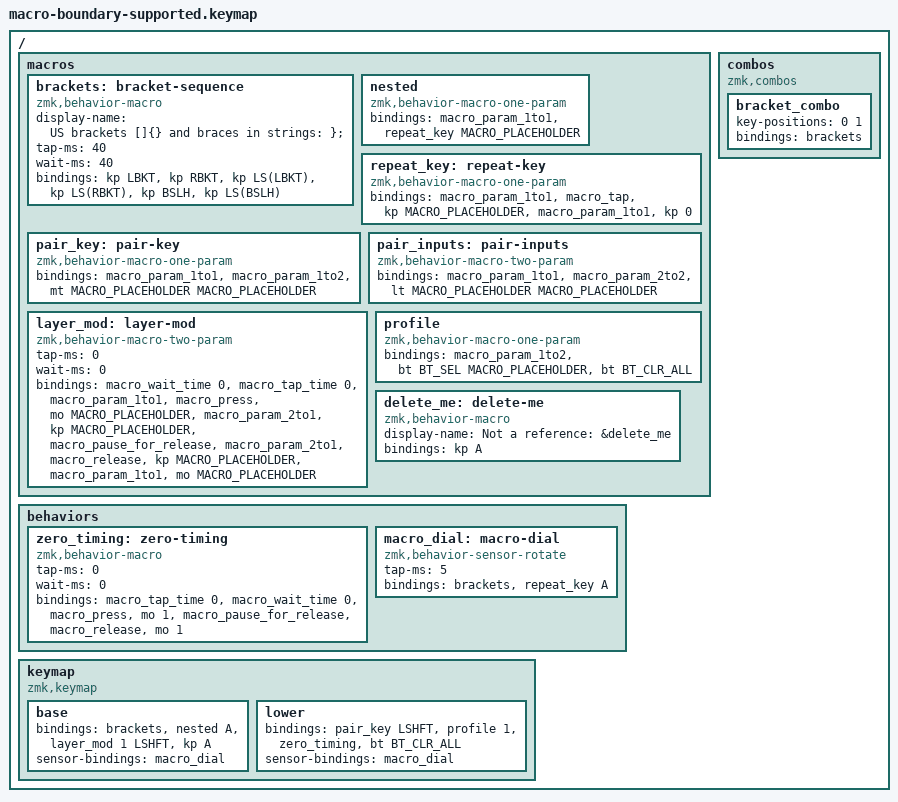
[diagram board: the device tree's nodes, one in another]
/*
 * CHG-005 Phase 1 specification input, not macro-authoring acceptance.
 * Current tests prove opaque source preservation, not the future matrix.
 * Synthetic US bracket/brace typing, forwarding, timing and reference graph.
 */
#include <behaviors.dtsi>
#include <dt-bindings/zmk/keys.h>
#include <dt-bindings/zmk/modifiers.h>
#include <dt-bindings/zmk/bt.h>

/ {
    macros {
        brackets: bracket-sequence {
            compatible = "zmk,behavior-macro";
            #binding-cells = <0>;
            display-name = "US brackets []{} and braces in strings: };";
            tap-ms = <40>;
            wait-ms = <40>;
            bindings = <&kp LBKT &kp RBKT>,
                       <&kp LS(LBKT) /* keep this comment */ &kp LS(RBKT)>,
                       <&kp BSLH &kp LS(BSLH)>;
        };

        // Declaration order must not determine reference resolution.
        nested: nested {
            compatible = "zmk,behavior-macro-one-param";
            #binding-cells = <1>;
            bindings = <&macro_param_1to1 &repeat_key MACRO_PLACEHOLDER>;
        };

        repeat_key: repeat-key {
            compatible = "zmk,behavior-macro-one-param";
            #binding-cells = <1>;
            bindings = <&macro_param_1to1 &macro_tap &kp MACRO_PLACEHOLDER>,
                       <&macro_param_1to1 &kp 0>;
        };

        pair_key: pair-key {
            compatible = "zmk,behavior-macro-one-param";
            #binding-cells = <1>;
            bindings = <&macro_param_1to1 &macro_param_1to2>,
                       <&mt MACRO_PLACEHOLDER MACRO_PLACEHOLDER>;
        };

        pair_inputs: pair-inputs {
            compatible = "zmk,behavior-macro-two-param";
            #binding-cells = <2>;
            bindings = <&macro_param_1to1 &macro_param_2to2>,
                       <&lt MACRO_PLACEHOLDER MACRO_PLACEHOLDER>;
        };

        layer_mod: layer-mod {
            compatible = "zmk,behavior-macro-two-param";
            #binding-cells = <2>;
            tap-ms = <0>;
            wait-ms = <0>;
            bindings = <&macro_wait_time 0 &macro_tap_time 0>,
                       <&macro_param_1to1 &macro_press &mo MACRO_PLACEHOLDER>,
                       <&macro_param_2to1 &kp MACRO_PLACEHOLDER>,
                       <&macro_pause_for_release>,
                       <&macro_param_2to1 &macro_release &kp MACRO_PLACEHOLDER>,
                       <&macro_param_1to1 &mo MACRO_PLACEHOLDER>;
        };

        profile: profile {
            compatible = "zmk,behavior-macro-one-param";
            #binding-cells = <1>;
            bindings = <&macro_param_1to2 &bt BT_SEL MACRO_PLACEHOLDER>,
                       <&bt BT_CLR_ALL>;
        };

        // &delete_me in a comment is not an incoming reference.
        delete_me: delete-me {
            compatible = "zmk,behavior-macro";
            #binding-cells = <0>;
            display-name = "Not a reference: &delete_me";
            bindings = <&kp A>;
        };
        // This following comment must survive deletion of the preceding node.
    };

    behaviors {
        zero_timing: zero-timing {
            compatible = "zmk,behavior-macro";
            #binding-cells = <0>;
            tap-ms = <0>;
            wait-ms = <0>;
            bindings = <&macro_tap_time 0 &macro_wait_time 0>,
                       <&macro_press &mo 1>,
                       <&macro_pause_for_release>,
                       <&macro_release &mo 1>;
        };

        macro_dial: macro-dial {
            compatible = "zmk,behavior-sensor-rotate";
            #sensor-binding-cells = <0>;
            tap-ms = <5>;
            bindings = <&brackets>, <&repeat_key A>;
        };
    };

    combos {
        compatible = "zmk,combos";
        bracket_combo {
            key-positions = <0 1>;
            bindings = <&brackets>;
        };
    };

    keymap {
        compatible = "zmk,keymap";
        base {
            bindings = <&brackets &nested A &layer_mod 1 LSHFT &kp A>;
            sensor-bindings = <&macro_dial>;
        };
        lower {
            bindings = <&pair_key LSHFT &profile 1 &zero_timing &bt BT_CLR_ALL>;
            sensor-bindings = <&macro_dial>;
        };
    };
};
